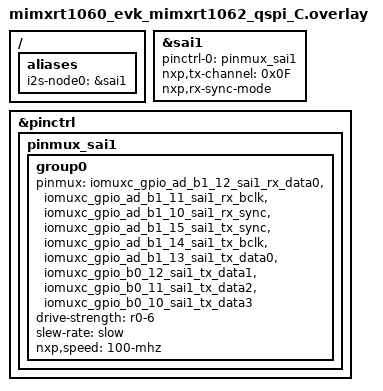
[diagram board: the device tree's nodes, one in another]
/ {
	aliases {
		i2s-node0 = &sai1;
	};
};

&sai1 {
	status = "okay";
	pinctrl-0 = <&pinmux_sai1>;
	pinctrl-names = "default";
	nxp,tx-channel = <0x0F>; /* Channels 0,1,2,3 */
	nxp,rx-sync-mode;
};

&pinctrl {
	pinmux_sai1: pinmux_sai1 {
		group0 {
			pinmux = <&iomuxc_gpio_ad_b1_12_sai1_rx_data0>,
				<&iomuxc_gpio_ad_b1_11_sai1_rx_bclk>,
				<&iomuxc_gpio_ad_b1_10_sai1_rx_sync>,
				<&iomuxc_gpio_ad_b1_15_sai1_tx_sync>,
				<&iomuxc_gpio_ad_b1_14_sai1_tx_bclk>,
				<&iomuxc_gpio_ad_b1_13_sai1_tx_data0>,
				<&iomuxc_gpio_b0_12_sai1_tx_data1>,
				<&iomuxc_gpio_b0_11_sai1_tx_data2>,
				<&iomuxc_gpio_b0_10_sai1_tx_data3>;
			drive-strength = "r0-6";
			slew-rate = "slow";
			nxp,speed = "100-mhz";
		};
	};
};
